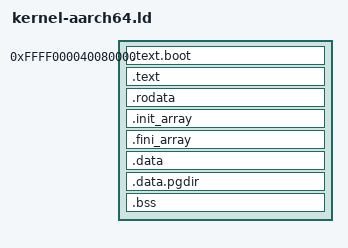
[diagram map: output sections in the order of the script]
OUTPUT_FORMAT("elf64-littleaarch64")
OUTPUT_ARCH(aarch64)
ENTRY(_start)

KERNEL_BASE = 0xFFFF000000000000;
KERNEL_PHYS = 0x40080000;            /* QEMU virt -kernel load address */

SECTIONS {
    . = KERNEL_BASE + KERNEL_PHYS;

    PROVIDE(KERNEL_START = .);

    .text.boot : AT(KERNEL_PHYS) {
        *(.text.boot)
    }

    .text : {
        *(.text .text.*)
    }

    .rodata : {
        *(.rodata .rodata.*)
    }

    /* C++ global constructors */
    .init_array : {
        PROVIDE(__init_array_start = .);
        KEEP(*(SORT(.init_array.*)))
        KEEP(*(.init_array))
        PROVIDE(__init_array_end = .);
    }

    .fini_array : {
        PROVIDE(__fini_array_start = .);
        KEEP(*(SORT(.fini_array.*)))
        KEEP(*(.fini_array))
        PROVIDE(__fini_array_end = .);
    }

    . = ALIGN(0x1000);
    .data : {
        *(.data)
    }

    . = ALIGN(0x1000);
    .data.pgdir : {
        *(.data.pgdir)
    }

    . = ALIGN(0x1000);
    .bss (NOLOAD) : {
        PROVIDE(__bss_start = .);
        *(.bss .bss.*)
        *(COMMON)
        PROVIDE(__bss_end = .);
    }

    PROVIDE(KERNEL_END = .);

    /DISCARD/ : {
        *(.eh_frame .note.GNU-stack .comment)
    }
}
